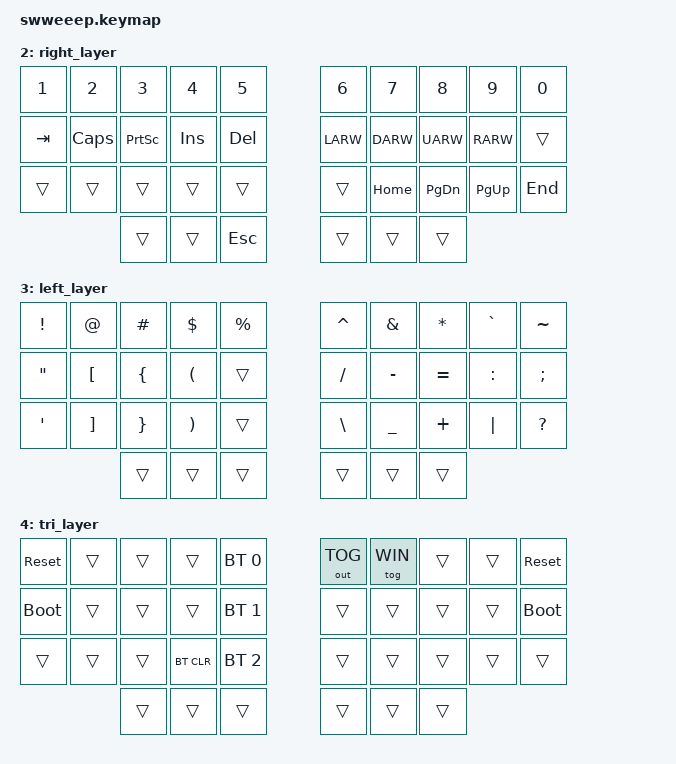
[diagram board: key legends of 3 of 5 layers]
#include <behaviors.dtsi>
#include <dt-bindings/zmk/keys.h>
#include <dt-bindings/zmk/bt.h>
#include <dt-bindings/zmk/ext_power.h>
#include <dt-bindings/zmk/outputs.h>

#define HRML(k1,k2,k3,k4) &ht LGUI k1  &ht LALT k2  &ht LCTRL k3  &ht LSHFT k4
#define HRMR(k1,k2,k3,k4) &ht RSHFT k1  &ht RCTRL k2  &ht RALT k3  &ht RGUI k4
#define WHRML(k1,k2,k3,k4) &ht LALT k1  &ht LGUI k2  &ht LCTRL k3 &ht RSHFT k4
#define WHRMR(k1,k2,k3,k4) &ht RSHFT k1  &ht RALT k2  &ht RGUI k3 &ht RCTRL k4

#define MAC 0
#define WIN 1
#define RIG 2
#define LEF 3
#define TRI 4


&caps_word {
    continue-list = <UNDERSCORE MINUS>;
};

/ {
    combos {
        compatible = "zmk,combos";
        combo_undo {
            timeout-ms = <50>;
            key-positions = <20 21>;
            bindings = <&kp LC(Z)>;
        };
    };
};

/ {

    behaviors {
        ht: homerow_mods {
            label = "hold_tap";
            compatible = "zmk,behavior-hold-tap";
            #binding-cells = <2>;
            tapping-term-ms = <220>;
            quick-tap-ms = <150>;
            global-quick-tap;
            flavor = "tap-preferred";
            bindings = <&kp>, <&kp>;
        };
    };

    conditional_layers {
        compatible = "zmk,conditional-layers";
        tri_layer {
            if-layers = <RIG LEF>;
            then-layer = <TRI>;
        };
    };

   keymap {
        compatible = "zmk,keymap";
        default_layer {
            bindings = <
        //╭──────────┬──────────┬──────────┬──────────┬──────────╮   ╭──────────┬──────────┬──────────┬──────────┬──────────╮
        //│  Q       │  W       │  E       │  R       │  T       │   │  Y       │  U       │  I       │  O       │  P       │
            &kp Q      &kp W      &kp E      &kp R      &kp T          &kp Y      &kp U      &kp I      &kp O      &kp P
        //├──────────┼──────────┼──────────┼──────────┼──────────┤   ├──────────┼──────────┼──────────┼──────────┼──────────┤
        //│  A       │  S       │  D       │  F       │  G       │   │  H       │  J       │  K       │  L       │ ' "      │
            HRML(A,        S,         D,         F)     &kp G          &kp H      HRMR(J,        K,         L,        SQT)
        //├──────────┼──────────┼──────────┼──────────┼──────────┤   ├──────────┼──────────┼──────────┼──────────┼──────────┤
        //│  Z       │  X       │  C       │  V       │  B       │   │  N       │  M       │ , <      │ . >      │ / ?      │
            &kp Z      &kp X      &kp C      &kp V      &kp B          &kp N      &kp M      &kp COMMA  &kp DOT    &kp FSLH
        //╰──────────┴──────────┴──────────┼──────────┼──────────┤   ├──────────┼──────────┼──────────┴──────────┴──────────╯
                                 &mo LEF     &kp LGUI   &kp SPACE     &kp ENTER   &kp BSPC   &mo RIG
        //                      ╰──────────┴──────────┴──────────╯   ╰──────────┴──────────┴──────────╯
            >;
        };

        windows_layer {
            bindings = <
        //╭──────────┬──────────┬──────────┬──────────┬──────────╮   ╭──────────┬──────────┬──────────┬──────────┬──────────╮
        //│  Q       │  W       │  E       │  R       │  T       │   │  Y       │  U       │  I       │  O       │  P       │
            &kp Q      &kp W      &kp E      &kp R      &kp T          &kp Y      &kp U      &kp I      &kp O      &kp P
        //├──────────┼──────────┼──────────┼──────────┼──────────┤   ├──────────┼──────────┼──────────┼──────────┼──────────┤
        //│  A       │  S       │  D       │  F       │  G       │   │  H       │  J       │  K       │  L       │BACKSPACE │
            WHRML(A,          S,         D,         F)     &kp G          &kp H      WHRMR(J,        K,      L,       BSPC)
        //├──────────┼──────────┼──────────┼──────────┼──────────┤   ├──────────┼──────────┼──────────┼──────────┼──────────┤
        //│  Z       │  X       │  C       │  V       │  B       │   │  N       │  M       │ , <      │ . >      │ ENTER    │
            &kp Z      &kp X      &kp C      &kp V      &kp B          &kp N      &kp M      &kp COMMA  &kp DOT    &kp ENTER
        //╰──────────┴──────────┴──────────┼──────────┼──────────┤   ├──────────┼──────────┼──────────┴──────────┴──────────╯
                                 &mo LEF     &kp LGUI   &kp SPACE     &kp ENTER  &kp BSPC    &mo RIG
        //                      ╰──────────┴──────────┴──────────╯   ╰──────────┴──────────┴──────────╯
            >;
        };

        right_layer {
            bindings = <
        //╭──────────┬──────────┬──────────┬──────────┬──────────╮   ╭──────────┬──────────┬──────────┬──────────┬──────────╮
        //│ 1        │  2       │  3       │  4       │  5       │   │ 6        │ 7        │ 8        │ 9        │   0      │
            &kp N1    &kp N2     &kp N3     &kp N4     &kp N5          &kp N6     &kp N7     &kp N8     &kp N9      &kp N0
        //├──────────┼──────────┼──────────┼──────────┼──────────┤   ├──────────┼──────────┼──────────┼──────────┼──────────┤
        //│ TAB      │ CapsLock │ PrintSc  │  INSERT  │ DELETE   |   |  LEFT    │ DOWN     │ UP       │ RIGHT    │          │
            &kp TAB   &kp CAPS   &kp PSCRN  &kp INS     &kp DEL        &kp LARW    &kp DARW   &kp UARW   &kp RARW   &trans
        //├──────────┼──────────┼──────────┼──────────┼──────────┤   ├──────────┼──────────┼──────────┼──────────┼──────────┤
        //│          │          │          │          │          │   │          │ HOME     │ PAGE DN  │ PAGE UP  │ END      │
            &trans    &trans     &trans     &trans      &trans           &trans     &kp HOME   &kp PG_DN  &kp PG_UP  &kp END
        //╰──────────┴──────────┴──────────┼──────────┼──────────┤   ├──────────┼──────────┼──────────┴──────────┴──────────╯
                                  &trans     &trans     &kp ESC         &trans     &trans     &trans
        //                      ╰──────────┴──────────┴──────────╯   ╰──────────┴──────────┴──────────╯
            >;
        };

        left_layer {
            bindings = <
        //╭──────────┬──────────┬──────────┬──────────┬──────────╮   ╭──────────┬──────────┬──────────┬──────────┬──────────╮
        //│  !       │  @       │  #       │  $       │  %       │   │  ^       │  &       │  *       │  `       │  ~       │
            &kp EXCL   &kp AT     &kp HASH   &kp DLLR   &kp PRCNT      &kp CARET  &kp AMPS   &kp ASTRK  &kp GRAVE   &kp TILDE
        //├──────────┼──────────┼──────────┼──────────┼──────────┤   ├──────────┼──────────┼──────────┼──────────┼──────────┤
        //│  "       │  [       │  {       │  (       │          │   │   /      │  -       │  =       │     :    │  ;       │
            &kp DQT    &kp LBKT   &kp LBRC   &kp LPAR   &trans         &kp FSLH   &kp MINUS  &kp EQUAL  &kp COLON   &kp SEMI
        //├──────────┼──────────┼──────────┼──────────┼──────────┤   ├──────────┼──────────┼──────────┼──────────┼──────────┤
        //│  '       │  ]       │  }       │  )       │          │   │    \     │  _       │  +       │  │       │   ?      │
            &kp SQT     &kp RBKT   &kp RBRC   &kp RPAR   &trans         &kp BSLH   &kp UNDER  &kp PLUS   &kp PIPE  &kp QMARK
        //╰──────────┴──────────┴──────────┼──────────┼──────────┤   ├──────────┼──────────┼──────────┴──────────┴──────────╯
                                  &trans     &trans     &trans         &trans     &trans     &trans
        //                      ╰──────────┴──────────┴──────────╯   ╰──────────┴──────────┴──────────╯
            >;
        };

        tri_layer {
            bindings = <
        //╭──────────┬──────────┬──────────┬──────────┬──────────╮   ╭──────────┬──────────┬──────────┬──────────┬──────────╮
        //│ RESET    │          │          │          │PROFILE 0 │   │TOGGLEOUT │ WINDOWS  │          │          │  RESET   │
           &sys_reset  &trans     &trans     &trans    &bt BT_SEL 0  &out OUT_TOG &tog WIN     &trans     &trans    &sys_reset
        //├──────────┼──────────┼──────────┼──────────┼──────────┤   ├──────────┼──────────┼──────────┼──────────┼──────────┤
        //│BOOTLOADER│          │          │          │PROFILE 1 │   │          │          │          │          │BOOTLOADER│
          &bootloader  &trans     &trans     &trans    &bt BT_SEL 1    &trans     &trans     &trans     &trans    &bootloader
        //├──────────┼──────────┼──────────┼──────────┼──────────┤   ├──────────┼──────────┼──────────┼──────────┼──────────┤
        //│          │          │          │ CLEAR BT │PROFILE 2 │   │          │          │          │          │          │
            &trans     &trans     &trans    &bt BT_CLR &bt BT_SEL 2    &trans     &trans     &trans     &trans     &trans
        //╰──────────┴──────────┴──────────┼──────────┼──────────┤   ├──────────┼──────────┼──────────┴──────────┴──────────╯
                                  &trans     &trans     &trans         &trans     &trans     &trans
        //                      ╰──────────┴──────────┴──────────╯   ╰──────────┴──────────┴──────────╯
            >;
        };
    };

};
